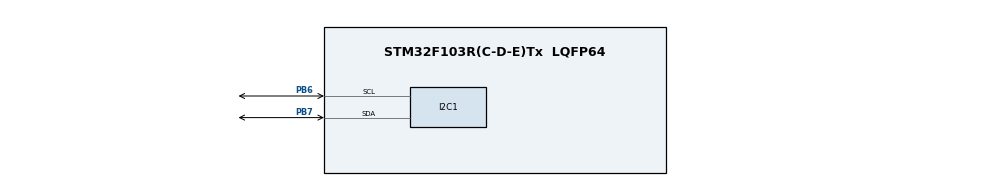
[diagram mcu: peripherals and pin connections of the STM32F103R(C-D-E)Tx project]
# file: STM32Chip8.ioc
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Mcu.Family=STM32F1
Mcu.Name=STM32F103R(C-D-E)Tx
Mcu.Package=LQFP64
NVIC.PriorityGroup=NVIC_PRIORITYGROUP_4
PA13.Mode=Serial_Wire
PA13.Signal=SYS_JTMS-SWDIO
PA14.Mode=Serial_Wire
PA14.Signal=SYS_JTCK-SWCLK
PB6.Mode=I2C
PB6.Signal=I2C1_SCL
PB7.Mode=I2C
PB7.Signal=I2C1_SDA
PD0-OSC_IN.Mode=HSE-External-Oscillator
PD0-OSC_IN.Signal=RCC_OSC_IN
PD1-OSC_OUT.Mode=HSE-External-Oscillator
PD1-OSC_OUT.Signal=RCC_OSC_OUT
ProjectManager.HeapSize=0x200
ProjectManager.StackSize=0x400
ProjectManager.TargetToolchain=STM32CubeIDE
RCC.APB1Freq_Value=8000000
RCC.APB2Freq_Value=8000000
RCC.SYSCLKSource=RCC_SYSCLKSOURCE_PLLCLK
board=custom

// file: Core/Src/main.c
/* USER CODE BEGIN Header */
/**
  ******************************************************************************
  * @file           : main.c
  * @brief          : Main program body
  ******************************************************************************
  * @attention
  *
  * <h2><center>&copy; Copyright (c) 2021 STMicroelectronics.
  * All rights reserved.</center></h2>
  *
  * This software component is licensed by ST under BSD 3-Clause license,
  * the "License"; You may not use this file except in compliance with the
  * License. You may obtain a copy of the License at:
  *                        opensource.org/licenses/BSD-3-Clause
  *
  ******************************************************************************
  */
/* USER CODE END Header */
#include "main.h"

/* USER CODE BEGIN Includes */
#include "ssd1306/ssd1306.h"
#include "game/splash.h"
#include "game/menu.h"
#include "game/games.h"
#include "game/chip8.h"

/* USER CODE END Includes */

I2C_HandleTypeDef hi2c1;

void SystemClock_Config(void);
static void MX_GPIO_Init(void);
static void MX_I2C1_Init(void);

int main(void)
{

  /* MCU Configuration--------------------------------------------------------*/

  /* Reset of all peripherals, Initializes the Flash interface and the Systick. */
  HAL_Init();

  /* Configure the system clock */
  SystemClock_Config();

  /* Initialize all configured peripherals */
  MX_GPIO_Init();
  MX_I2C1_Init();
  /* USER CODE BEGIN 2 */
  ssd1306_Init();

//  ssd1306_Fill(White);
//  ssd1306_UpdateScreen();
//  HAL_Delay(500);
//  ssd1306_Fill(Black);
//  ssd1306_UpdateScreen();
//  HAL_Delay(500);

  splashScreenShow();
  HAL_Delay(100);

  unsigned int game = 4;//menuSelectGame();
  chip8ResetMem(game_data[game], game_size[game]);
  chip8ResetCpu();

  unsigned long current_millis;
  unsigned long last_millis = 0;
  char pressed = 0;
  /* USER CODE END 2 */

  /* Infinite loop */
  /* USER CODE BEGIN WHILE */
  while (1)
  {
      current_millis = HAL_GetTick();
      if ((current_millis - last_millis) >= (1000 / 60))
      {
          last_millis = current_millis;

//          chip8UpdateKey(0x0, inputRead(0x0));
//          chip8UpdateKey(0x1, inputRead(0x1));
//          chip8UpdateKey(0x2, inputRead(0x2));
//          chip8UpdateKey(0x3, inputRead(0x3));
//          chip8UpdateKey(0x4, inputRead(0x4));
//          chip8UpdateKey(0x5, inputRead(0x5));
//          chip8UpdateKey(0x6, inputRead(0x6));
//          chip8UpdateKey(0x7, inputRead(0x7));
//          chip8UpdateKey(0x8, inputRead(0x8));
//          chip8UpdateKey(0x9, inputRead(0x9));
//          chip8UpdateKey(0xA, inputRead(0xA));
//          chip8UpdateKey(0xB, inputRead(0xB));
//          chip8UpdateKey(0xC, inputRead(0xC));
//          chip8UpdateKey(0xD, inputRead(0xD));
//          chip8UpdateKey(0xE, inputRead(0xE));
//          chip8UpdateKey(0xF, inputRead(0xF));

//          if (pressed == 0)  {
//        	  chip8UpdateKey(0x0, 1);
//        	  pressed = 1;
//          }

          chip8StepCpu(game_frequency[game] / 10);

//          if (chip8GetAudio())
//          {
//              buzzerBeep();
//          }
//          else
//          {
//              buzzerSilent();
//          }

          chip8UpdateTimers();

          displayRefresh(chip8GetScreen());
      }
    /* USER CODE END WHILE */

  }
}

void SystemClock_Config(void)
{
  RCC_OscInitTypeDef RCC_OscInitStruct = {0};
  RCC_ClkInitTypeDef RCC_ClkInitStruct = {0};

  /** Initializes the RCC Oscillators according to the specified parameters
  * in the RCC_OscInitTypeDef structure.
  */
  RCC_OscInitStruct.OscillatorType = RCC_OSCILLATORTYPE_HSI;
  RCC_OscInitStruct.HSIState = RCC_HSI_ON;
  RCC_OscInitStruct.HSICalibrationValue = RCC_HSICALIBRATION_DEFAULT;
  RCC_OscInitStruct.PLL.PLLState = RCC_PLL_ON;
  RCC_OscInitStruct.PLL.PLLSource = RCC_PLLSOURCE_HSI_DIV2;
  RCC_OscInitStruct.PLL.PLLMUL = RCC_PLL_MUL2;
  if (HAL_RCC_OscConfig(&RCC_OscInitStruct) != HAL_OK)
  {
    Error_Handler();
  }
  /** Initializes the CPU, AHB and APB buses clocks
  */
  RCC_ClkInitStruct.ClockType = RCC_CLOCKTYPE_HCLK|RCC_CLOCKTYPE_SYSCLK
                              |RCC_CLOCKTYPE_PCLK1|RCC_CLOCKTYPE_PCLK2;
  RCC_ClkInitStruct.SYSCLKSource = RCC_SYSCLKSOURCE_PLLCLK;
  RCC_ClkInitStruct.AHBCLKDivider = RCC_SYSCLK_DIV1;
  RCC_ClkInitStruct.APB1CLKDivider = RCC_HCLK_DIV1;
  RCC_ClkInitStruct.APB2CLKDivider = RCC_HCLK_DIV1;

  if (HAL_RCC_ClockConfig(&RCC_ClkInitStruct, FLASH_LATENCY_0) != HAL_OK)
  {
    Error_Handler();
  }
}

static void MX_I2C1_Init(void)
{

  hi2c1.Instance = I2C1;
  hi2c1.Init.ClockSpeed = 100000;
  hi2c1.Init.DutyCycle = I2C_DUTYCYCLE_2;
  hi2c1.Init.OwnAddress1 = 0;
  hi2c1.Init.AddressingMode = I2C_ADDRESSINGMODE_7BIT;
  hi2c1.Init.DualAddressMode = I2C_DUALADDRESS_DISABLE;
  hi2c1.Init.OwnAddress2 = 0;
  hi2c1.Init.GeneralCallMode = I2C_GENERALCALL_DISABLE;
  hi2c1.Init.NoStretchMode = I2C_NOSTRETCH_DISABLE;
  if (HAL_I2C_Init(&hi2c1) != HAL_OK)
  {
    Error_Handler();
  }

}

static void MX_GPIO_Init(void)
{

  /* GPIO Ports Clock Enable */
  __HAL_RCC_GPIOD_CLK_ENABLE();
  __HAL_RCC_GPIOA_CLK_ENABLE();
  __HAL_RCC_GPIOB_CLK_ENABLE();

}

void Error_Handler(void)
{
  __disable_irq();
  while (1)
  {
  }
}

/************************ (C) COPYRIGHT STMicroelectronics *****END OF FILE****/
